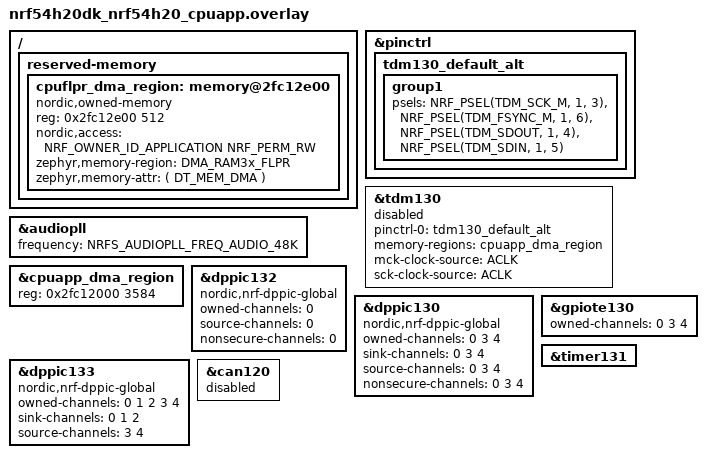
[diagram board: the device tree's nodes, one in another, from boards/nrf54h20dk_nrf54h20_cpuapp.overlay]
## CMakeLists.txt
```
# SPDX-License-Identifier: Apache-2.0

cmake_minimum_required(VERSION 3.20.0)
find_package(Zephyr REQUIRED HINTS $ENV{ZEPHYR_BASE})
project(usb_audio_async_i2s)

include(${ZEPHYR_BASE}/samples/subsys/usb/common/common.cmake)
target_sources(app PRIVATE src/main.c src/periphconf.c)

if (CONFIG_SOC_COMPATIBLE_NRF5340_CPUAPP OR CONFIG_SOC_SERIES_NRF54HX)
	target_sources(app PRIVATE src/feedback_nrf.c)
else()
	target_sources(app PRIVATE src/feedback_dummy.c)
endif()
```

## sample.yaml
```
sample:
  name: USB Audio 2 asynchronous implicit feedback sample
tests:
  sample.subsys.usb.uac2_implicit_feedback:
    depends_on:
      - usbd
      - i2s
    tags:
      - usb
      - i2s
    extra_configs:
      - CONFIG_CLOCK_CONTROL_NRF=n
    platform_allow:
      - nrf5340dk/nrf5340/cpuapp
      - nrf54h20dk/nrf54h20/cpuapp
    harness: TBD

  sample.subsys.usb.uac2_implicit_feedback.legacy:
    depends_on:
      - usbd
      - i2s
    tags:
      - usb
      - i2s
    extra_configs:
      - CONFIG_CLOCK_CONTROL_NRF=y
    platform_allow:
      - nrf5340dk/nrf5340/cpuapp
      - nrf54h20dk/nrf54h20/cpuapp
    harness: TBD
```

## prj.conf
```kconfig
CONFIG_I2S=n
CONFIG_CLOCK_CONTROL=y
CONFIG_CLOCK_CONTROL_NRFS_AUDIOPLL=y
#USB related configs
CONFIG_USB_DEVICE_STACK_NEXT=y
CONFIG_CDC_ACM_SERIAL_INITIALIZE_AT_BOOT=n
CONFIG_USBD_AUDIO2_CLASS=y
CONFIG_SAMPLE_USBD_PID=0x000F
CONFIG_SAMPLE_USBD_PRODUCT="UAC2 implicit feedback sample"

#LOG subsystem related configs
CONFIG_LOG=y
CONFIG_USBD_LOG_LEVEL_WRN=y
CONFIG_UDC_DRIVER_LOG_LEVEL_WRN=y
```

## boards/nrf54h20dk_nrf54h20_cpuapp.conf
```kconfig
CONFIG_UDC_DWC2_PTI=y
CONFIG_NRFX_TIMER130=y
# Enable timer for asynchronous feedback
CONFIG_NRFX_GPPI=y
CONFIG_NRFX_TIMER131=y
```

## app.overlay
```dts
/*
 * Copyright (c) 2023 Nordic Semiconductor ASA
 *
 * SPDX-License-Identifier: Apache-2.0
 */

#include <dt-bindings/usb/audio.h>

/ {
	uac2_headset: usb_audio2 {
		compatible = "zephyr,uac2";
		status = "okay";
		high-speed;
		audio-function = <AUDIO_FUNCTION_HEADSET>;

		uac_aclk: aclk {
			compatible = "zephyr,uac2-clock-source";
			clock-type = "internal-programmable";
			frequency-control = "host-programmable";
			sampling-frequencies = <48000>;
		};

		out_terminal: out_terminal {
			compatible = "zephyr,uac2-input-terminal";
			clock-source = <&uac_aclk>;
			terminal-type = <USB_TERMINAL_STREAMING>;
			front-left;
			front-right;
		};

		headphones_output: headphones {
			compatible = "zephyr,uac2-output-terminal";
			data-source = <&out_terminal>;
			clock-source = <&uac_aclk>;
			terminal-type = <BIDIRECTIONAL_TERMINAL_HEADSET>;
			assoc-terminal = <&mic_input>;
		};

		mic_input: microphone {
			compatible = "zephyr,uac2-input-terminal";
			clock-source = <&uac_aclk>;
			terminal-type = <BIDIRECTIONAL_TERMINAL_HEADSET>;
			/* Circular reference, macros will figure it out and
			 * provide correct associated terminal ID because the
			 * terminals associations are always 1-to-1.
			 *
			 * assoc-terminal = <&headphones_output>;
			 */
			front-left;
			front-right;
			back-left;
			back-right;
			side-left;
			side-right;
		};

		in_terminal: in_terminal {
			compatible = "zephyr,uac2-output-terminal";
			data-source = <&mic_input>;
			clock-source = <&uac_aclk>;
			terminal-type = <USB_TERMINAL_STREAMING>;
		};

		as_iso_out: out_interface {
			compatible = "zephyr,uac2-audio-streaming";
			linked-terminal = <&out_terminal>;
			implicit-feedback;
			subslot-size = <4>;
			bit-resolution = <32>;
			polling-period-us = <500>;
		};

		as_iso_in: in_interface {
			compatible = "zephyr,uac2-audio-streaming";
			linked-terminal = <&in_terminal>;
			implicit-feedback;
			subslot-size = <4>;
			bit-resolution = <32>;
			polling-period-us = <500>;
		};
	};
};

&gpio9 {
	status = "reserved";
};

&cpuflpr_vpr {
	status = "okay";
};
```

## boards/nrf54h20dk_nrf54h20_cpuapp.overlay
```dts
/*
 * Copyright (c) 2025 Nordic Semiconductor ASA
 *
 * SPDX-License-Identifier: Apache-2.0
 */

#include "../app.overlay"

&pinctrl {
	tdm130_default_alt: tdm130_default_alt {
		group1 {
			psels = <NRF_PSEL(TDM_SCK_M, 1, 3)>,
				<NRF_PSEL(TDM_FSYNC_M, 1, 6)>,
				<NRF_PSEL(TDM_SDOUT, 1, 4)>,
				<NRF_PSEL(TDM_SDIN, 1, 5)>;
		};
	};
};

i2s_rxtx: &tdm130 {
	status = "reserved";
	pinctrl-0 = <&tdm130_default_alt>;
	pinctrl-names = "default";
	memory-regions = <&cpuapp_dma_region>;
	mck-clock-source = "ACLK";
	sck-clock-source = "ACLK";
};

&audiopll {
	frequency = <NRFS_AUDIOPLL_FREQ_AUDIO_48K>;
	status = "okay";
};

/* Reduce app dma region to allow RAM3x space for FLPR (TDM). */
&cpuapp_dma_region {
	status = "okay";
	reg = <0x2fc12000 3584>;
};

/ {
	reserved-memory {
		cpuflpr_dma_region: memory@2fc12e00 {
			compatible = "nordic,owned-memory", "zephyr,memory-region";
			reg = <0x2fc12e00 512>;
			status = "okay";
			#memory-region-cells = <0>;
			nordic,access = <NRF_OWNER_ID_APPLICATION NRF_PERM_RW>;
			zephyr,memory-region = "DMA_RAM3x_FLPR";
			zephyr,memory-attr = <( DT_MEM_DMA )>;
		};
	};
};

/* PPI channel 0 for TDM130 MAXCNT */
&dppic132 {
	compatible = "nordic,nrf-dppic-global";
	owned-channels = <0>;
	source-channels = <0>;
	nonsecure-channels = <0>;
	status = "okay";
};

/* TDM130 PPI needs routing to TIMER131 through main APB */
&dppic130 {
	compatible = "nordic,nrf-dppic-global";
	owned-channels = <0 3 4>;
	sink-channels = <0 3 4>;
	source-channels = <0 3 4>;
	nonsecure-channels = <0 3 4>;
	status = "okay";
};

/* TIMER131 PPI channel 1 is used for SOF and channel 2 for decimated SOF */
&dppic133 {
	compatible = "nordic,nrf-dppic-global";
	owned-channels = <0 1 2 3 4>;
	sink-channels = <0 1 2>;
	source-channels = <3 4>;
	status = "okay";
};

&gpiote130 {
	status = "okay";
	owned-channels = <0 3 4>;
};

&timer131 {
	status = "okay";
};

/* To allow use of 9.4 and 9.5 pins for debugging. */
&can120 {
	status = "disabled";
};
```

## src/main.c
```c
/*
 * Copyright (c) 2023-2024 Nordic Semiconductor ASA
 *
 * SPDX-License-Identifier: Apache-2.0
 */

#include <stdint.h>
#include <stdlib.h>

#include <sample_usbd.h>
#include "feedback.h"

#include <zephyr/device.h>
#include <zephyr/usb/usbd.h>
#include <zephyr/usb/class/usbd_uac2.h>
#include <zephyr/drivers/i2s.h>
#include <zephyr/drivers/clock_control/nrf_clock_control.h>
#include <zephyr/logging/log.h>
#include <zephyr/linker/devicetree_regions.h>

LOG_MODULE_REGISTER(uac2_sample, LOG_LEVEL_INF);

#define HEADPHONES_OUT_TERMINAL_ID UAC2_ENTITY_ID(DT_NODELABEL(out_terminal))
#define MICROPHONE_IN_TERMINAL_ID UAC2_ENTITY_ID(DT_NODELABEL(in_terminal))

#define FS_SAMPLES_PER_SOF  (48 * FULL_SPEED_SOF_PERIODS)
#define HS_SAMPLES_PER_SOF  (6 * HIGH_SPEED_SOF_PERIODS)
#define MAX_SAMPLES_PER_SOF MAX(FS_SAMPLES_PER_SOF, HS_SAMPLES_PER_SOF)
#define SAMPLE_FREQUENCY    (FS_SAMPLES_PER_SOF * 1000)
#define SAMPLE_BIT_WIDTH    16
#define NUMBER_OF_CHANNELS  2
#define BYTES_PER_SAMPLE    DIV_ROUND_UP(SAMPLE_BIT_WIDTH, 8)
#define BYTES_PER_SLOT      (BYTES_PER_SAMPLE * NUMBER_OF_CHANNELS)
#define MIN_BLOCK_SIZE      ((MAX_SAMPLES_PER_SOF - 1) * BYTES_PER_SLOT)
#define BLOCK_SIZE          (MAX_SAMPLES_PER_SOF * BYTES_PER_SLOT)
#define MAX_BLOCK_SIZE      ((MAX_SAMPLES_PER_SOF + 1) * BYTES_PER_SLOT)

#define I2S_MEMORY_SECTION __noinit

/* Absolute minimum is 5 TX buffers (1 actively consumed by I2S, 2nd queued as
 * next buffer, 3rd acquired by USB stack to receive data to, and 2 to handle
 * SOF/I2S offset errors), but add 2 additional buffers to prevent out of memory
 * errors when USB host decides to perform rapid terminal enable/disable cycles.
 */
#define I2S_BLOCKS          7
K_MEM_SLAB_DEFINE_IN_SECT_STATIC(i2s_tx_slab, I2S_MEMORY_SECTION,
	ROUND_UP(MAX_BLOCK_SIZE, UDC_BUF_GRANULARITY), I2S_BLOCKS, UDC_BUF_ALIGN);
K_MEM_SLAB_DEFINE_IN_SECT_STATIC(i2s_rx_slab, I2S_MEMORY_SECTION,
	ROUND_UP(MAX_BLOCK_SIZE, UDC_BUF_GRANULARITY), I2S_BLOCKS, UDC_BUF_ALIGN);

#define I2S_ENABLED IS_ENABLED(CONFIG_I2S)

struct usb_i2s_ctx {
	const struct device *i2s_dev;
	bool headphones_enabled;
	bool microphone_enabled;
	bool i2s_started;
	bool rx_started;
	bool microframes;
	uint8_t sofs_after_data_recv;
	uint8_t sofs_after_in;
	/* Counter used to determine when to start I2S and then when to start
	 * sending RX packets to host. Overflows are not a problem because this
	 * variable is not necessary after both I2S and RX is started.
	 */
	uint8_t i2s_counter;
	struct feedback_ctx *fb;

	/* Leftover samples from I2S receive buffer, already compacted to mono,
	 * that were not sent to host. The buffer, if not NULL, is allocated
	 * from I2S RX slab.
	 */
	uint8_t *pending_mic_buf;
	uint8_t pending_mic_samples;

	/* Rolling bit buffers for tracking nominal + 1 and nominal - 1 samples
	 * sent. Bits are mutually exclusive, i.e.:
	 *   plus_ones | minus_ones = plus_ones ^ minus_ones
	 *
	 * Used to avoid overcompensation in feedback regulator. LSBs indicate
	 * latest write size.
	 */
	uint32_t plus_ones;
	uint32_t minus_ones;

	enum {
		ISO_IN_NOT_SYNCHRONIZED,
		ISO_IN_ZLP_QUEUED,
		ISO_IN_SYNCHRONIZED,
	} iso_in_sync;
};

static void uac2_terminal_update_cb(const struct device *dev, uint8_t terminal,
				    bool enabled, bool microframes,
				    void *user_data)
{
	struct usb_i2s_ctx *ctx = user_data;

	ctx->microframes = microframes;

	if (terminal == HEADPHONES_OUT_TERMINAL_ID) {
		ctx->headphones_enabled = enabled;
	} else if (terminal == MICROPHONE_IN_TERMINAL_ID) {
		ctx->microphone_enabled = enabled;
	}
#if I2S_ENABLED
	if (ctx->i2s_started && !ctx->headphones_enabled &&
	    !ctx->microphone_enabled) {
		i2s_trigger(ctx->i2s_dev, I2S_DIR_BOTH, I2S_TRIGGER_DROP);
		ctx->i2s_started = false;
		ctx->rx_started = false;
		ctx->i2s_counter = 0;
		ctx->plus_ones = ctx->minus_ones = 0;
		if (ctx->pending_mic_samples) {
			k_mem_slab_free(&i2s_rx_slab, ctx->pending_mic_buf);
			ctx->pending_mic_buf = NULL;
			ctx->pending_mic_samples = 0;
		}
		feedback_reset_ctx(ctx->fb);
		ctx->iso_in_sync = ISO_IN_NOT_SYNCHRONIZED;
	}
#endif
}

#if I2S_ENABLED
static int nominal_samples_per_sof(struct usb_i2s_ctx *ctx)
{
	if (USBD_SUPPORTS_HIGH_SPEED && ctx->microframes) {
		return HS_SAMPLES_PER_SOF;
	}

	return FS_SAMPLES_PER_SOF;
}
#endif

static void *uac2_get_recv_buf(const struct device *dev, uint8_t terminal,
			       uint16_t size, void *user_data)
{
	ARG_UNUSED(dev);
	struct usb_i2s_ctx *ctx = user_data;
	void *buf = NULL;

	if (terminal == HEADPHONES_OUT_TERMINAL_ID) {
		__ASSERT_NO_MSG(size <= MAX_BLOCK_SIZE);

		if (!ctx->headphones_enabled) {
			LOG_ERR("Buffer request on disabled terminal");
			return NULL;
		}
#if I2S_ENABLED
		int ret = k_mem_slab_alloc(&i2s_tx_slab, &buf, K_NO_WAIT);
		if (ret != 0) {
			buf = NULL;
		}
#endif
	}

	return buf;
}

static void uac2_data_recv_cb(const struct device *dev, uint8_t terminal,
			      void *buf, uint16_t size, void *user_data)
{
#if I2S_ENABLED
	struct usb_i2s_ctx *ctx = user_data;
	int nominal = nominal_samples_per_sof(ctx);
	int ret;

	ctx->sofs_after_data_recv = 0;

	if (!ctx->headphones_enabled && !ctx->microphone_enabled) {
		k_mem_slab_free(&i2s_tx_slab, buf);
		return;
	}

	if (!size) {
		/* This code path is expected when host only records microphone
		 * data and is not streaming any audio to the headphones. Simply
		 * transmit as many zero-filled samples were last sent to allow
		 * the feedback regulator to work.
		 *
		 * When host is streaming audio, this can be a transient error.
		 * While the "feedback regulator delay" is likely to differ,
		 * it is still probably best to just zero-fill last sent number
		 * of samples. If we overcompensate as a result, the situation
		 * will stabilize after a while anyway.
		 *
		 * In either case, we have to keep I2S going and the only way
		 * we can control the SOF to I2S offset is by varying the number
		 * of samples sent.
		 */
		if (ctx->plus_ones & 1) {
			size = (nominal + 1) * BYTES_PER_SLOT;
		} else if (ctx->minus_ones & 1) {
			size = (nominal - 1) * BYTES_PER_SLOT;
		} else {
			size = nominal * BYTES_PER_SLOT;
		}
		memset(buf, 0, size);
	}

	LOG_DBG("Received %d data to input terminal %d", size, terminal);

	ret = i2s_write(ctx->i2s_dev, buf, size);

	if (ret < 0) {
		ctx->i2s_started = false;
		ctx->rx_started = false;
		ctx->i2s_counter = 0;
		ctx->plus_ones = ctx->minus_ones = 0;
		if (ctx->pending_mic_samples) {
			k_mem_slab_free(&i2s_rx_slab, ctx->pending_mic_buf);
			ctx->pending_mic_buf = NULL;
			ctx->pending_mic_samples = 0;
		}

		/* Most likely underrun occurred, prepare I2S restart */
		i2s_trigger(ctx->i2s_dev, I2S_DIR_BOTH, I2S_TRIGGER_DROP);

		ret = i2s_write(ctx->i2s_dev, buf, size);
		if (ret < 0) {
			/* Drop data block, will try again on next frame */
			k_mem_slab_free(&i2s_tx_slab, buf);
		}
	}

	if (ret == 0) {
		ctx->i2s_counter++;
	}
#endif
}

static void uac2_buf_release_cb(const struct device *dev, uint8_t terminal,
				void *buf, void *user_data)
{
#if I2S_ENABLED
	struct usb_i2s_ctx *ctx = user_data;

	if (terminal == MICROPHONE_IN_TERMINAL_ID) {
		if (ctx->iso_in_sync == ISO_IN_ZLP_QUEUED) {
			if (ctx->microphone_enabled) {
				ctx->iso_in_sync = ISO_IN_SYNCHRONIZED;
			} else {
				ctx->iso_in_sync = ISO_IN_NOT_SYNCHRONIZED;
			}
		}
		ctx->sofs_after_in = 0;
		k_mem_slab_free(&i2s_rx_slab, buf);
	}
#endif
}

#if I2S_ENABLED
/* Determine next number of samples to send, called at most once every SOF */
static int next_mic_num_samples(struct usb_i2s_ctx *ctx)
{
	int nominal = nominal_samples_per_sof(ctx);
	int offset = feedback_samples_offset(ctx->fb);

	/* The rolling buffers essentially handle controller dead time, i.e.
	 * the buffers are used to prevent overcompensating on feedback offset.
	 * Remove the oldest entry by shifting the values by one bit.
	 */
	ctx->plus_ones <<= 1;
	ctx->minus_ones <<= 1;

	/* At Full-Speed only remember last 8 frames */
	if (!USBD_SUPPORTS_HIGH_SPEED || !ctx->microframes) {
		ctx->plus_ones &= 0x000000FF;
		ctx->minus_ones &= 0x000000FF;
	}

	if ((offset < 0) && (POPCOUNT(ctx->plus_ones) < -offset)) {
		/* I2S buffer starts at least 1 sample before SOF, send nominal
		 * + 1 samples to host in order to shift offset towards 0.
		 */
		ctx->plus_ones |= 1;
		return nominal + 1;
	}

	if ((offset > 0) && (POPCOUNT(ctx->minus_ones) < offset)) {
		/* I2S buffer starts at least 1 sample after SOF, send nominal
		 * - 1 samples to host in order to shift offset towards 0
		 */
		ctx->minus_ones |= 1;
		return nominal - 1;
	}

	/* I2S is either spot on, or the offset is expected to correct soon */
	return nominal;
}

static void process_mic_data(const struct device *dev, struct usb_i2s_ctx *ctx)
{
	size_t num_bytes;
	uint8_t *dst, *src;
	uint8_t *mic_buf;
	void *rx_block;
	int ret;
	int samples_to_send, mic_samples, rx_samples, leftover_samples;

	samples_to_send = next_mic_num_samples(ctx);

	if (ctx->pending_mic_samples >= samples_to_send) {
		/* No need to fetch new I2S samples, this happens shortly after
		 * we have "borrowed" samples from next buffer. This is expected
		 * and means that the streams have synchronized.
		 */
		rx_block = NULL;
		rx_samples = 0;
	} else {
		ret = i2s_read(ctx->i2s_dev, &rx_block, &num_bytes);
		if (ret) {
			/* No data available, I2S will restart soon */
			return;
		}

		/* I2S operates on 2 channels (stereo) */
		rx_samples = num_bytes / (BYTES_PER_SAMPLE * 2);
	}

	/* Prepare microphone data to send, use pending samples if any */
	src = rx_block;
	if (ctx->pending_mic_buf) {
		mic_buf = ctx->pending_mic_buf;
		mic_samples = ctx->pending_mic_samples;
		dst = &ctx->pending_mic_buf[mic_samples * BYTES_PER_SAMPLE];
	} else if (rx_samples >= 1) {
		/* First sample is already in place */
		mic_buf = rx_block;
		dst = &mic_buf[BYTES_PER_SAMPLE];
		src += 2 * BYTES_PER_SAMPLE;
		mic_samples = 1;
		rx_samples--;
	} else {
		/* Something went horribly wrong, free the buffer and leave */
		k_mem_slab_free(&i2s_rx_slab, rx_block);
		return;
	}

	/* Copy as many samples as possible, stop if mic buffer is ready */
	while ((mic_samples < samples_to_send) && (rx_samples > 0)) {
		memcpy(dst, src, BYTES_PER_SAMPLE);

		dst += BYTES_PER_SAMPLE;
		src += 2 * BYTES_PER_SAMPLE;

		mic_samples++;
		rx_samples--;
	}

	/* Is mic buffer ready to go? */
	if (mic_samples < samples_to_send) {
		/* No, we have to borrow sample from next buffer. This can only
		 * happen if we fully drained current receive buffer.
		 */
		__ASSERT_NO_MSG(rx_samples == 0);

		if (rx_block != mic_buf) {
			/* RX buffer no longer needed, samples are in mic_buf */
			k_mem_slab_free(&i2s_rx_slab, rx_block);
		}

		ret = i2s_read(ctx->i2s_dev, &rx_block, &num_bytes);
		if (ret) {
			/* No data, I2S will likely restart due to error soon */
			ctx->pending_mic_buf = mic_buf;
			ctx->pending_mic_samples = mic_samples;
			return;
		}

		src = rx_block;
		rx_samples = num_bytes / (BYTES_PER_SAMPLE * 2);
	}

	/* Copy remaining sample, under normal conditions (i.e. connected to
	 * non-malicious host) this is guaranteed to fully fill mic_buf.
	 */
	while ((mic_samples < samples_to_send) && (rx_samples > 0)) {
		memcpy(dst, src, BYTES_PER_SAMPLE);

		dst += BYTES_PER_SAMPLE;
		src += 2 * BYTES_PER_SAMPLE;

		mic_samples++;
		rx_samples--;
	}

	/* Are we still short on samples? */
	if (mic_samples < samples_to_send) {
		/* The only possibility for this code to execute is that we were
		 * short on samples and the next block (pointed to by rx_block)
		 * did not contain enough samples to fill the gap.
		 */
		__ASSERT_NO_MSG(rx_block != mic_buf);

		/* Bailing out at this point likely leads to faster recovery.
		 * Note that this should never happen during normal operation.
		 */
		ctx->pending_mic_buf = mic_buf;
		ctx->pending_mic_samples = mic_samples;

		/* RX buffer is no longer needed */
		k_mem_slab_free(&i2s_rx_slab, rx_block);
		return;
	}

	/* Handle any potential leftover, start by sanitizing length */
	leftover_samples = mic_samples - samples_to_send + rx_samples;
	if (leftover_samples > (MAX_BLOCK_SIZE / BYTES_PER_SAMPLE)) {
		size_t dropped_samples =
			leftover_samples - (MAX_BLOCK_SIZE / BYTES_PER_SAMPLE);

		LOG_WRN("Too many leftover samples, dropping %d samples",
			dropped_samples);
		if (rx_samples >= dropped_samples) {
			rx_samples -= dropped_samples;
		} else {
			mic_samples -= (dropped_samples - rx_samples);
			rx_samples = 0;
		}

		leftover_samples = (MAX_BLOCK_SIZE / BYTES_PER_SAMPLE);
	}

	if (leftover_samples == 0) {
		/* No leftover samples */
		if ((rx_block != NULL) && (rx_block != mic_buf)) {
			/* All samples were copied, free source buffer */
			k_mem_slab_free(&i2s_rx_slab, rx_block);
		}
		rx_block = NULL;
	} else if ((mic_samples > samples_to_send) ||
		   ((rx_samples > 0) && (rx_block == mic_buf))) {
		/* Leftover samples have to be copied to new buffer */
		ret = k_mem_slab_alloc(&i2s_rx_slab, &rx_block, K_NO_WAIT);
		if (ret != 0) {
			LOG_WRN("Out of memory dropping %d samples",
				leftover_samples);
			mic_samples = samples_to_send;
			rx_samples = 0;
			rx_block = NULL;
		}
	}

	/* At this point rx_block is either
	 *   * NULL if there are no leftover samples, OR
	 *   * src buffer if leftover data can be copied from back to front, OR
	 *   * brand new buffer if there is leftover data in mic buffer.
	 */
	ctx->pending_mic_buf = rx_block;
	ctx->pending_mic_samples = 0;

	/* Copy excess samples from pending mic buf, if any */
	if (mic_samples > samples_to_send) {
		size_t bytes;

		/* Samples in mic buffer are already compacted */
		bytes = (mic_samples - samples_to_send) * BYTES_PER_SAMPLE;
		memcpy(ctx->pending_mic_buf, &mic_buf[mic_samples], bytes);

		ctx->pending_mic_samples = mic_samples - samples_to_send;
		dst = &ctx->pending_mic_buf[bytes];
	} else {
		dst = ctx->pending_mic_buf;
	}

	/* Copy excess samples from src buffer, so we don't lose any */
	while (rx_samples > 0) {
		memcpy(dst, src, BYTES_PER_SAMPLE);

		dst += BYTES_PER_SAMPLE;
		src += 2 * BYTES_PER_SAMPLE;

		ctx->pending_mic_samples++;
		rx_samples--;
	}

	/* Finally send the microphone samples to host */
	if (usbd_uac2_send(dev, MICROPHONE_IN_TERMINAL_ID,
			   mic_buf, mic_samples * BYTES_PER_SAMPLE) < 0) {
		k_mem_slab_free(&i2s_rx_slab, mic_buf);
	}
}

static uint32_t get_sof_periods(struct usb_i2s_ctx *ctx)
{
	if (USBD_SUPPORTS_HIGH_SPEED && ctx->microframes) {
		return HIGH_SPEED_SOF_PERIODS;
	}

	return FULL_SPEED_SOF_PERIODS;
}

static bool is_zero_fill_needed(const struct device *dev, struct usb_i2s_ctx *ctx)
{
	uint32_t sof_periods = get_sof_periods(ctx);

	if (!ctx->microphone_enabled && !ctx->headphones_enabled) {
		/* Streaming is not active, zero fill is not necessary */
		return false;
	}

	/* Should the isochronous IN synchronization be handled here?
	 * Currently the USB stack is not (micro-)frame aware at all.
	 * What type of interface should we have?
	 */
	if (sof_periods > 1 && ctx->microphone_enabled &&
	    ctx->iso_in_sync == ISO_IN_NOT_SYNCHRONIZED) {
		void *buf;
		int ret;

		ret = k_mem_slab_alloc(&i2s_rx_slab, &buf, K_NO_WAIT);
		if (ret == 0) {
			if (usbd_uac2_send(dev, MICROPHONE_IN_TERMINAL_ID,
					   buf, 0) < 0) {
				k_mem_slab_free(&i2s_rx_slab, buf);
			} else {
				ctx->iso_in_sync = ISO_IN_ZLP_QUEUED;
			}
		}

		/* We don't know when we should expect the data - do not zero
		 * fill. USB hosts tend to write zeroes first before real data,
		 * so we should be fine with delaying I2S startup.
		 */
		return false;
	}

	if (sof_periods > 1) {
		/* bInterval is higher than one which means there is some wiggle
		 * room as to when we have to supply missing data. Use this to
		 * actually supply missing data one SOF later than expected.
		 * This mitigates an issue where data receive callback is called
		 * after subsequent SOF, i.e. out of order. This can happen for
		 * example on DWC2 when both isochronous OUT XferCompl and SOF
		 * interrupt bits are set when the interrupt handler executes
		 * (it is impossible to tell which one happened first).
		 */
		sof_periods += 1;
	}

	return ctx->sofs_after_data_recv >= sof_periods;
}

static bool is_i2s_start_needed(const struct device *dev, struct usb_i2s_ctx *ctx)
{
	const uint32_t sof_periods = get_sof_periods(ctx);

	/* For bInterval=1 we are always "IN synchronized" */
	if (sof_periods == 1 || ctx->iso_in_sync == ISO_IN_SYNCHRONIZED) {
		ctx->sofs_after_data_recv++;
		ctx->sofs_after_in = (ctx->sofs_after_in + 1) % sof_periods;
	} else {
		/* Wait for host to start polling isochronous IN endpoint */
		return false;
	}

	if (ctx->i2s_started) {
		/* We are already started, no need to trigger start */
		return false;
	}

	/* We want to maintain 3 SOFs delay, i.e. samples received from host
	 * during SOF n should be transmitted on I2S during SOF n+3. This
	 * provides enough wiggle room for software scheduling that effectively
	 * eliminates "buffers not provided in time" problem.
	 *
	 * ">= 2" translates into 3 SOFs delay because the timeline is:
	 * USB SOF n
	 *   OUT DATA0 n received from host
	 * USB SOF n+1
	 *   DATA0 n is available to UDC driver (See Universal Serial Bus
	 *   Specification Revision 2.0 5.12.5 Data Prebuffering) and copied
	 *   to I2S buffer before SOF n+2; i2s_counter = 1
	 *   OUT DATA0 n+1 received from host
	 * USB SOF n+2
	 *   DATA0 n+1 is copied; i2s_counter = 2
	 *   OUT DATA0 n+2 received from host
	 * USB SOF n+3
	 *   This function triggers I2S start
	 *   DATA0 n+2 is copied; i2s_counter is no longer relevant
	 *   OUT DATA0 n+3 received from host
	 */
	if ((ctx->headphones_enabled || ctx->microphone_enabled) &&
	    ctx->i2s_counter >= 2 && ctx->sofs_after_in == 0) {
		return true;
	}

	return false;
}

static bool is_mic_processing_needed(struct usb_i2s_ctx *ctx)
{
	const uint32_t sof_periods = get_sof_periods(ctx);

	if (!ctx->rx_started) {
		return false;
	}

	if (sof_periods == 1) {
		/* We have to process microphone data on every SOF */
		return true;
	}

	/* Process microphone data after first SOF within interval */
	return ctx->sofs_after_in == 1;
}
#endif

static void uac2_sof(const struct device *dev, void *user_data)
{
	ARG_UNUSED(dev);
#if I2S_ENABLED
	struct usb_i2s_ctx *ctx = user_data;

	if (ctx->i2s_started) {
		feedback_process(ctx->fb);
	}

	/* If we didn't receive data since last SOF but either terminal is
	 * enabled, then we have to come up with the buffer ourself to keep
	 * I2S going.
	 */
	if (is_zero_fill_needed(dev, ctx)) {
		/* No data received since last SOF but we have to keep going */
		void *buf;
		int ret;

		ret = k_mem_slab_alloc(&i2s_tx_slab, &buf, K_NO_WAIT);
		if (ret != 0) {
			buf = NULL;
		}

		if (buf) {
			/* Use size 0 to utilize zero-fill functionality */
			uac2_data_recv_cb(dev, HEADPHONES_OUT_TERMINAL_ID,
					  buf, 0, user_data);
			ctx->sofs_after_data_recv += 1;
		}
	}

	if (is_i2s_start_needed(dev, ctx)) {
		i2s_trigger(ctx->i2s_dev, I2S_DIR_BOTH, I2S_TRIGGER_START);
		ctx->i2s_started = true;
		feedback_start(ctx->fb, ctx->i2s_counter, ctx->microframes);
		ctx->i2s_counter = 0;
	}

	/* Start sending I2S RX data only when there are at least 3 buffers
	 * ready with data. This guarantees that there'll always be a buffer
	 * available from which sample can be borrowed.
	 */
	if (!ctx->rx_started && ctx->i2s_started && ctx->i2s_counter >= 3) {
		ctx->rx_started = true;
	}

	if (is_mic_processing_needed(ctx)) {
		process_mic_data(dev, ctx);
	}
#endif
}

static struct uac2_ops usb_audio_ops = {
	.sof_cb = uac2_sof,
	.terminal_update_cb = uac2_terminal_update_cb,
	.get_recv_buf = uac2_get_recv_buf,
	.data_recv_cb = uac2_data_recv_cb,
	.buf_release_cb = uac2_buf_release_cb,
};

static struct usb_i2s_ctx main_ctx;

#if !I2S_ENABLED
static void clock_started_callback(struct onoff_manager *mgr, struct onoff_client *cli,
				   uint32_t state, int res)
{
	LOG_INF("Clock ok");
}
#endif

int main(void)
{
	const struct device *dev = DEVICE_DT_GET(DT_NODELABEL(uac2_headset));
	struct usbd_context *sample_usbd;
	int ret;

#if I2S_ENABLED
	struct i2s_config config;
	main_ctx.i2s_dev = DEVICE_DT_GET(DT_NODELABEL(i2s_rxtx));

	if (!device_is_ready(main_ctx.i2s_dev)) {
		printk("%s is not ready\n", main_ctx.i2s_dev->name);
		return 0;
	}

	config.word_size = SAMPLE_BIT_WIDTH;
	config.channels = NUMBER_OF_CHANNELS;
	config.format = I2S_FMT_DATA_FORMAT_I2S;
	config.options = I2S_OPT_BIT_CLK_MASTER | I2S_OPT_FRAME_CLK_MASTER;
	config.frame_clk_freq = SAMPLE_FREQUENCY;
	config.mem_slab = &i2s_tx_slab;
	config.block_size = MAX_BLOCK_SIZE;
	config.timeout = 0;

	ret = i2s_configure(main_ctx.i2s_dev, I2S_DIR_TX, &config);
	if (ret < 0) {
		printk("Failed to configure TX stream: %d\n", ret);
		return 0;
	}

	config.mem_slab = &i2s_rx_slab;
	ret = i2s_configure(main_ctx.i2s_dev, I2S_DIR_RX, &config);
	if (ret < 0) {
		printk("Failed to configure RX stream: %d\n", ret);
		return 0;
	}
#else
#define NODE_ACLK      DT_NODELABEL(audiopll)
#define ACLK_FREQUENCY DT_PROP_OR(NODE_ACLK, frequency, 0)

	static const struct device *audiopll = DEVICE_DT_GET(NODE_ACLK);
	static const struct nrf_clock_spec aclk_spec = {
		.frequency = ACLK_FREQUENCY,
	};
	struct onoff_client clk_cli;

	sys_notify_init_callback(&clk_cli.notify, clock_started_callback);
	ret = nrf_clock_control_request(audiopll, &aclk_spec, &clk_cli);
	if (ret < 0) {
		printk("Failed to request clock: %d\n", ret);
		return 0;
	}
#endif

	main_ctx.fb = feedback_init();

	usbd_uac2_set_ops(dev, &usb_audio_ops, &main_ctx);

	sample_usbd = sample_usbd_init_device(NULL);
	if (sample_usbd == NULL) {
		return -ENODEV;
	}

	ret = usbd_enable(sample_usbd);
	if (ret) {
		return ret;
	}

	return 0;
}
```

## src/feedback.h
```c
/*
 * Copyright (c) 2024 Nordic Semiconductor ASA
 *
 * SPDX-License-Identifier: Apache-2.0
 */

#ifndef FEEDBACK_H_
#define FEEDBACK_H_

#include <stdint.h>
#include <stdbool.h>
#include <zephyr/devicetree.h>
#include <zephyr/usb/usbd.h>

/* This sample is currently supporting only 48 kHz sample rate. */
#define SAMPLE_RATE         48000

#if IS_ENABLED(CONFIG_SOC_NRF54H20_CPUFLPR)
/* FIXME: This needs to match USB descriptors when USB streaming is added */
#define HIGH_SPEED_SOF_PERIODS 4
#define FULL_SPEED_SOF_PERIODS 1
#else

/* This check is broken if there is no polling period
BUILD_ASSERT(UTIL_AND(
	IS_EQ(DT_NODE_HAS_PROP(DT_NODELABEL(as_iso_in), polling_period_us),
	      DT_NODE_HAS_PROP(DT_NODELABEL(as_iso_out), polling_period_us)),
	IS_EQ(DT_PROP(DT_NODELABEL(as_iso_in), polling_period_us),
	      DT_PROP(DT_NODELABEL(as_iso_out), polling_period_us))),
	"Sample requires common IN and OUT polling periods");
*/
#define FS_SOF_PERIODS(us) BIT(USB_FS_ISO_EP_INTERVAL(us) - 1)
#define HS_SOF_PERIODS(us) BIT(USB_HS_ISO_EP_INTERVAL(us) - 1)

#define FS_PERIOD_US DT_PROP_OR(DT_NODELABEL(as_iso_in), polling_period_us, 1000)
#define HS_PERIOD_US DT_PROP_OR(DT_NODELABEL(as_iso_in), polling_period_us, 125)

#define HIGH_SPEED_SOF_PERIODS HS_SOF_PERIODS(HS_PERIOD_US)
#define FULL_SPEED_SOF_PERIODS FS_SOF_PERIODS(FS_PERIOD_US)
#endif

#if (USBD_SUPPORTS_HIGH_SPEED && HS_PERIOD_US >= 250) || (FS_PERIOD_US >= 2000)
#define SOF_PERIOD_TRACKING_NEEDED 1
#else
#define SOF_PERIOD_TRACKING_NEEDED 0
#endif

struct feedback_ctx *feedback_init(void);
void feedback_reset_ctx(struct feedback_ctx *ctx);
void feedback_process(struct feedback_ctx *ctx);
void feedback_start(struct feedback_ctx *ctx, int i2s_blocks_queued,
                    bool microframes);

/* Return offset between I2S block start and USB SOF in samples.
 *
 * Positive offset means that I2S block started at least 1 sample after SOF and
 * to correct the situation, shorter than nominal buffers are needed.
 *
 * Negative offset means that I2S block started at least 1 sample before SOF and
 * to correct the situation, larger than nominal buffers are needed.
 *
 * Offset 0 means that I2S block started within 1 sample around SOF. This is the
 * dominant value expected during normal operation.
 */
int feedback_samples_offset(struct feedback_ctx *ctx);

#endif /* FEEDBACK_H_ */
```

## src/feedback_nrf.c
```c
/*
 * Copyright (c) 2024 Nordic Semiconductor ASA
 *
 * SPDX-License-Identifier: Apache-2.0
 */
#include "feedback.h"
#include <zephyr/sys/util.h>

#if IS_ENABLED(CONFIG_SOC_NRF54H20_CPUFLPR)
#define DO_INIT 0
#else
#define DO_INIT 1
#endif

#if DO_INIT
#include <stdlib.h>
#include <zephyr/logging/log.h>
#include <nrfx_dppi.h>
#include <nrfx_timer.h>
#include <helpers/nrfx_gppi.h>
LOG_MODULE_REGISTER(feedback, LOG_LEVEL_INF);
#else
#include <hal/nrf_timer.h>
#endif


#define FEEDBACK_TIMER_USBD_SOF_CAPTURE 0
#define FEEDBACK_TIMER_I2S_FRAMESTART_CAPTURE 1

#if IS_ENABLED(CONFIG_SOC_COMPATIBLE_NRF5340_CPUAPP)

#include <hal/nrf_usbd.h>
#include <hal/nrf_i2s.h>

#define FEEDBACK_TIMER_INSTANCE_NUMBER 2
#define USB_SOF_EVENT_ADDRESS nrf_usbd_event_address_get(NRF_USBD, NRF_USBD_EVENT_SOF)
#define I2S_FRAMESTART_EVENT_ADDRESS nrf_i2s_event_address_get(NRF_I2S0, NRF_I2S_EVENT_FRAMESTART)

static inline void feedback_target_init(void)
{
	/* No target specific init necessary */
}

static inline void feedback_target_start(bool microframes)
{
	ARG_UNUSED(microframes);
}

#if SOF_PERIOD_TRACKING_NEEDED
#error "bInterval values other than 1 are currently not supported"
#endif

#elif IS_ENABLED(CONFIG_SOC_SERIES_NRF54HX)

#if DO_INIT
#include <nrfx_gpiote.h>
#include <nrfx_timer.h>
#include <helpers/nrfx_gppi.h>

static const nrfx_gpiote_t gpiote = NRFX_GPIOTE_INSTANCE(130);

#define GPIOTE_PPI_SOF_PIN    (9 * 32)
#define GPIOTE_PPI_MAXCNT_PIN (9 * 32) + 1
#define GPIOTE_PPI_BASE_SOF_PIN (1 * 32) + 0

static uint32_t gpiote_setup(uint32_t pin)
{
	uint8_t gpiote_ch;
	nrfx_err_t err;

	err = nrfx_gpiote_channel_alloc(&gpiote, &gpiote_ch);
	if (err != NRFX_SUCCESS) {
		LOG_ERR("failed to allocate gpiote");
		return 0;
	}

	nrfx_gpiote_task_config_t task_config = {
		.task_ch = gpiote_ch,
		.polarity = NRF_GPIOTE_POLARITY_TOGGLE,
		.init_val = NRF_GPIOTE_INITIAL_VALUE_LOW
	};
	nrfx_gpiote_output_config_t out_config = {
		.drive = NRF_GPIO_PIN_S0S1,
		.input_connect = NRF_GPIO_PIN_INPUT_DISCONNECT,
		.pull = NRF_GPIO_PIN_NOPULL
	};

	err = nrfx_gpiote_output_configure(&gpiote, pin, &out_config, &task_config);
	if (err != NRFX_SUCCESS) {
		LOG_ERR("failed to configure pin");
		return 0;
	}

	nrfx_gpiote_out_task_enable(&gpiote, pin);

	return nrfx_gpiote_out_task_address_get(&gpiote, pin);
}

#include <hal/nrf_tdm.h>

#define FEEDBACK_TIMER_INSTANCE_NUMBER 131
#define I2S_FRAMESTART_EVENT_ADDRESS nrf_tdm_event_address_get(NRF_TDM130, NRF_TDM_EVENT_MAXCNT)

#if SOF_PERIOD_TRACKING_NEEDED
/* bInterval != 1 support requires separate timer to decimate SOF */
#define SOF_DECIMATOR_TIMER_INSTANCE_NUMBER 130
#define SOF_DECIMATOR_COUNT_ADDRESS nrf_timer_task_address_get(NRF_TIMER130, NRF_TIMER_TASK_COUNT)

static const nrfx_timer_t sof_decimator_timer_instance =
	NRFX_TIMER_INSTANCE(SOF_DECIMATOR_TIMER_INSTANCE_NUMBER);

static void sof_decimator_init(void)
{
	nrfx_err_t err;
	uint8_t usbd_sof_gppi_channel;
	const nrfx_timer_config_t cfg = {
		.frequency = NRFX_MHZ_TO_HZ(16UL),
		.mode = NRF_TIMER_MODE_COUNTER,
		.bit_width = NRF_TIMER_BIT_WIDTH_32,
		.interrupt_priority = NRFX_TIMER_DEFAULT_CONFIG_IRQ_PRIORITY,
		.p_context = NULL,
	};

	err = nrfx_timer_init(&sof_decimator_timer_instance, &cfg, NULL);
	if (err != NRFX_SUCCESS) {
		LOG_ERR("SOF nrfx timer init error - Return value: %d", err);
		return;
	}

	nrfx_timer_extended_compare(&sof_decimator_timer_instance, NRF_TIMER_CC_CHANNEL1,
		HIGH_SPEED_SOF_PERIODS, NRF_TIMER_SHORT_COMPARE1_CLEAR_MASK, false);

	/* Subscribe TIMER CAPTURE task to USBD SOF event */
	err = nrfx_gppi_channel_alloc(&usbd_sof_gppi_channel);
	if (err != NRFX_SUCCESS) {
		LOG_ERR("gppi_channel_alloc failed with: %d\n", err);
		return;
	}

	nrfx_gppi_channel_endpoints_setup(usbd_sof_gppi_channel,
		nrf_timer_event_address_get(NRF_TIMER131, NRF_TIMER_EVENT_COMPARE5),
		gpiote_setup(GPIOTE_PPI_BASE_SOF_PIN));
	nrfx_gppi_fork_endpoint_setup(usbd_sof_gppi_channel,
		SOF_DECIMATOR_COUNT_ADDRESS);

	nrfx_gppi_channels_enable(BIT(usbd_sof_gppi_channel));

	nrfx_timer_enable(&sof_decimator_timer_instance);

	/****************************************************/
#define GPIOTE_RXPTRUPD (1*32+8)
#define GPIOTE_TXPTRUPD (1*32+9)
	err = nrfx_gppi_channel_alloc(&usbd_sof_gppi_channel);
	if (err != NRFX_SUCCESS) {
		LOG_ERR("gppi_channel_alloc failed with: %d\n", err);
		return;
	}
	nrfx_gppi_channel_endpoints_setup(usbd_sof_gppi_channel,
		nrf_tdm_event_address_get(NRF_TDM130, NRF_TDM_EVENT_RXPTRUPD),
		gpiote_setup(GPIOTE_RXPTRUPD));
	nrfx_gppi_channels_enable(BIT(usbd_sof_gppi_channel));

	err = nrfx_gppi_channel_alloc(&usbd_sof_gppi_channel);
	if (err != NRFX_SUCCESS) {
		LOG_ERR("gppi_channel_alloc failed with: %d\n", err);
		return;
	}
	nrfx_gppi_channel_endpoints_setup(usbd_sof_gppi_channel,
		nrf_tdm_event_address_get(NRF_TDM130, NRF_TDM_EVENT_TXPTRUPD),
		gpiote_setup(GPIOTE_TXPTRUPD));
	nrfx_gppi_channels_enable(BIT(usbd_sof_gppi_channel));
}

static inline void feedback_target_start(bool microframes)
{
	nrfx_timer_compare(&sof_decimator_timer_instance, NRF_TIMER_CC_CHANNEL1,
		microframes ? HIGH_SPEED_SOF_PERIODS : FULL_SPEED_SOF_PERIODS,
		false);

	nrfx_timer_clear(&sof_decimator_timer_instance);
}
#define USB_SOF_EVENT_ADDRESS nrf_timer_event_address_get(NRF_TIMER130, NRF_TIMER_EVENT_COMPARE1)
#else
/* bInterval=1, use SOF event directly */
#define USB_SOF_EVENT_ADDRESS nrf_timer_event_address_get(NRF_TIMER131, NRF_TIMER_EVENT_COMPARE5)

static inline void feedback_target_start(bool microframes)
{
	ARG_UNUSED(microframes);
}

static inline void sof_decimator_init(void)
{
	/* SOF decimator is not used */
}
#endif

static inline void feedback_target_init(void)
{
	/* Enable Start-of-Frame workaround in TIMER131 */
	*(volatile uint32_t *)0x5F9A3C04 = 0x00000002;
	*(volatile uint32_t *)0x5F9A3C04 = 0x00000003;
	*(volatile uint32_t *)0x5F9A3C80 = 0x00000082;

	sof_decimator_init();
}
#endif

#else
#error "Unsupported target"
#endif

#if DO_INIT
static const nrfx_timer_t feedback_timer_instance =
	NRFX_TIMER_INSTANCE(FEEDBACK_TIMER_INSTANCE_NUMBER);
#endif

/* While it might be possible to determine I2S FRAMESTART to USB SOF offset
 * entirely in software, the I2S API lacks appropriate timestamping. Therefore
 * this sample uses target-specific code to perform the measurements. Note that
 * the use of dedicated target-specific peripheral essentially eliminates
 * software scheduling jitter and it is likely that a pure software only
 * solution would require additional filtering in indirect offset measurements.
 *
 * Use timer clock (independent from both Audio clock and USB host SOF clock)
 * values directly to determine samples offset. This works fine because the
 * regulator cares only about error (SOF offset is both error and regulator
 * input) and achieves its goal by sending nominal + 1 or nominal - 1 samples.
 * SOF offset is around 0 when regulated and therefore the relative clock
 * frequency discrepancies are essentially negligible.
 */
#define CLKS_PER_SAMPLE	(16000000 / (SAMPLE_RATE))

static struct feedback_ctx {
	int32_t rel_sof_offset;
	int32_t base_sof_offset;
	int nominal;
} fb_ctx;

struct feedback_ctx *feedback_init(void)
{
#if DO_INIT
	nrfx_err_t err;
	uint8_t usbd_sof_gppi_channel;
	uint8_t i2s_framestart_gppi_channel;
	const nrfx_timer_config_t cfg = {
		.frequency = NRFX_MHZ_TO_HZ(16UL),
		.mode = NRF_TIMER_MODE_TIMER,
		.bit_width = NRF_TIMER_BIT_WIDTH_32,
		.interrupt_priority = NRFX_TIMER_DEFAULT_CONFIG_IRQ_PRIORITY,
		.p_context = NULL,
	};

	feedback_target_init();
#endif

	feedback_reset_ctx(&fb_ctx);

#if DO_INIT
	err = nrfx_timer_init(&feedback_timer_instance, &cfg, NULL);
	if (err != NRFX_SUCCESS) {
		LOG_ERR("nrfx timer init error - Return value: %d", err);
		return &fb_ctx;
	}

	/* Subscribe TIMER CAPTURE task to USBD SOF event */
	err = nrfx_gppi_channel_alloc(&usbd_sof_gppi_channel);
	if (err != NRFX_SUCCESS) {
		LOG_ERR("gppi_channel_alloc failed with: %d\n", err);
		return &fb_ctx;
	}

	/* GPIOTE needs to hop through bridge, so we have to set it up first.
	 * The "forks" are not hopping through, and the GPIOTE would fail if
	 * setup was called with USB SOF to TIMER CAPTURE.
	 */
	nrfx_gppi_channel_endpoints_setup(usbd_sof_gppi_channel,
		USB_SOF_EVENT_ADDRESS,
		gpiote_setup(GPIOTE_PPI_SOF_PIN));
	nrfx_gppi_fork_endpoint_setup(usbd_sof_gppi_channel,
		nrfx_timer_capture_task_address_get(&feedback_timer_instance,
			FEEDBACK_TIMER_USBD_SOF_CAPTURE));
	nrfx_gppi_fork_endpoint_setup(usbd_sof_gppi_channel,
		nrfx_timer_task_address_get(&feedback_timer_instance,
			NRF_TIMER_TASK_CLEAR));

	nrfx_gppi_channels_enable(BIT(usbd_sof_gppi_channel));

	/* Subscribe TIMER CAPTURE task to I2S FRAMESTART event */
	err = nrfx_gppi_channel_alloc(&i2s_framestart_gppi_channel);
	if (err != NRFX_SUCCESS) {
		LOG_ERR("gppi_channel_alloc failed with: %d\n", err);
		return &fb_ctx;
	}

	nrfx_gppi_channel_endpoints_setup(i2s_framestart_gppi_channel,
		I2S_FRAMESTART_EVENT_ADDRESS,
		nrfx_timer_capture_task_address_get(&feedback_timer_instance,
			FEEDBACK_TIMER_I2S_FRAMESTART_CAPTURE));
	nrfx_gppi_fork_endpoint_setup(i2s_framestart_gppi_channel,
		gpiote_setup(GPIOTE_PPI_MAXCNT_PIN));

	nrfx_gppi_channels_enable(BIT(i2s_framestart_gppi_channel));

	/* Enable feedback timer */
	nrfx_timer_enable(&feedback_timer_instance);
#endif

	return &fb_ctx;
}

static void update_sof_offset(struct feedback_ctx *ctx, uint32_t sof_cc,
			      uint32_t framestart_cc)
{
	int sof_offset;

	/* /2 because we treat the middle as a turning point from being
	 * "too late" to "too early".
	 */
	if (framestart_cc > (ctx->nominal * CLKS_PER_SAMPLE)/2) {
		sof_offset = framestart_cc - ctx->nominal * CLKS_PER_SAMPLE;
	} else {
		sof_offset = framestart_cc;
	}

	/* The heuristic above is not enough when the offset gets too large.
	 * If the sign of the simple heuristic changes, check whether the offset
	 * crossed through the zero or the outer bound.
	 */
	if ((ctx->rel_sof_offset >= 0) != (sof_offset >= 0)) {
		uint32_t abs_diff;
		int32_t base_change;

		if (sof_offset >= 0) {
			abs_diff = sof_offset - ctx->rel_sof_offset;
			base_change = -(ctx->nominal * CLKS_PER_SAMPLE);
		} else {
			abs_diff = ctx->rel_sof_offset - sof_offset;
			base_change = ctx->nominal * CLKS_PER_SAMPLE;
		}

		/* Adjust base offset only if the change happened through the
		 * outer bound. The actual changes should be significantly lower
		 * than the threshold here.
		 */
		if (abs_diff > (ctx->nominal * CLKS_PER_SAMPLE)/2) {
			ctx->base_sof_offset += base_change;
		}
	}

	ctx->rel_sof_offset = sof_offset;
}

void feedback_process(struct feedback_ctx *ctx)
{
	uint32_t sof_cc;
	uint32_t framestart_cc;

#if DO_INIT
	sof_cc = nrfx_timer_capture_get(&feedback_timer_instance,
		FEEDBACK_TIMER_USBD_SOF_CAPTURE);
	framestart_cc = nrfx_timer_capture_get(&feedback_timer_instance,
		FEEDBACK_TIMER_I2S_FRAMESTART_CAPTURE);
#else
	sof_cc = nrf_timer_cc_get(NRF_TIMER131, FEEDBACK_TIMER_USBD_SOF_CAPTURE);
	framestart_cc = nrf_timer_cc_get(NRF_TIMER131, FEEDBACK_TIMER_I2S_FRAMESTART_CAPTURE);
#endif

	update_sof_offset(ctx, sof_cc, framestart_cc);
}

void feedback_reset_ctx(struct feedback_ctx *ctx)
{
	ARG_UNUSED(ctx);
}

void feedback_start(struct feedback_ctx *ctx, int i2s_blocks_queued,
		    bool microframes)
{
#if DO_INIT
	feedback_target_start(microframes);
#endif

	if (microframes) {
		ctx->nominal = HIGH_SPEED_SOF_PERIODS * SAMPLE_RATE / 8000;
	} else {
		ctx->nominal = FULL_SPEED_SOF_PERIODS * SAMPLE_RATE / 1000;
	}

	/* I2S data was supposed to go out at SOF, but it is inevitably
	 * delayed due to triggering I2S start by software. Set relative
	 * SOF offset value in a way that ensures that values past "half
	 * frame" are treated as "too late" instead of "too early"
	 */
	ctx->rel_sof_offset = (ctx->nominal * CLKS_PER_SAMPLE) / 2;
	/* If there are more than 2 I2S TX blocks queued, use feedback regulator
	 * to correct the situation.
	 */
	ctx->base_sof_offset = (i2s_blocks_queued - 2) *
		(ctx->nominal * CLKS_PER_SAMPLE);
}

int feedback_samples_offset(struct feedback_ctx *ctx)
{
	int32_t offset = ctx->rel_sof_offset + ctx->base_sof_offset;

	return offset / CLKS_PER_SAMPLE;
}
```
